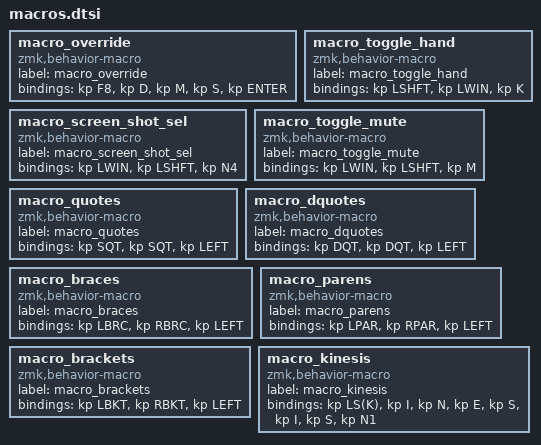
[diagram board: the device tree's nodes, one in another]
macro_override: macro_override{
compatible = "zmk,behavior-macro";
label = "macro_override";
#binding-cells = <0>;
bindings = <&kp F8>, <&kp D>, <&kp M>, <&kp S>, <&kp ENTER>;
};
macro_toggle_hand: macro_toggle_hand{
compatible = "zmk,behavior-macro";
label = "macro_toggle_hand";
#binding-cells = <0>;
bindings = <&kp LSHFT>, <&kp LWIN>, <&kp K>;
};
macro_screen_shot_sel: macro_screen_shot_sel{
compatible = "zmk,behavior-macro";
label = "macro_screen_shot_sel";
#binding-cells = <0>;
bindings = <&kp LWIN>, <&kp LSHFT>, <&kp N4>;
};
macro_toggle_mute: macro_toggle_mute{
compatible = "zmk,behavior-macro";
label = "macro_toggle_mute";
#binding-cells = <0>;
bindings = <&kp LWIN>, <&kp LSHFT>, <&kp M>;
};
macro_quotes: macro_quotes{
compatible = "zmk,behavior-macro";
label = "macro_quotes";
#binding-cells = <0>;
bindings = <&kp SQT>, <&kp SQT>, <&kp LEFT>;
};
macro_dquotes: macro_dquotes{
compatible = "zmk,behavior-macro";
label = "macro_dquotes";
#binding-cells = <0>;
bindings = <&kp DQT>, <&kp DQT>, <&kp LEFT>;
};
macro_braces: macro_braces{
compatible = "zmk,behavior-macro";
label = "macro_braces";
#binding-cells = <0>;
bindings = <&kp LBRC>, <&kp RBRC>, <&kp LEFT>;
};
macro_parens: macro_parens{
compatible = "zmk,behavior-macro";
label = "macro_parens";
#binding-cells = <0>;
bindings = <&kp LPAR>, <&kp RPAR>, <&kp LEFT>;
};
macro_brackets: macro_brackets{
compatible = "zmk,behavior-macro";
label = "macro_brackets";
#binding-cells = <0>;
bindings = <&kp LBKT>, <&kp RBKT>, <&kp LEFT>;
};
macro_kinesis: macro_kinesis{
compatible = "zmk,behavior-macro";
label = "macro_kinesis";
#binding-cells = <0>;
bindings = <&kp LS(K)>, <&kp I>, <&kp N>, <&kp E>, <&kp S>, <&kp I>, <&kp S>, <&kp N1>;
};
